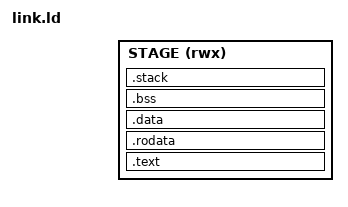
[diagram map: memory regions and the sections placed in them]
/* Lichen v3 boot stage (#615). One region (region.ld, generated by build.rs: STAGE_BASE, STAGE_LEN): the loaded image
 * first, then bss and the stack. The stage is written to 0x2000..0x7FFF (24 KB) one day, so check.sh holds the
 * packed image to 24576 bytes. Never writes outside its region; the kernel it chains to loads below 0x4FF28ED0. */
OUTPUT_ARCH(riscv)
ENTRY(_start)
INCLUDE region.ld
MEMORY {
  STAGE (rwx) : ORIGIN = STAGE_BASE, LENGTH = STAGE_LEN
}
SECTIONS {
  .text : { KEEP(*(.text.boot)) *(.text.trap) *(.text .text.*) } > STAGE
  .rodata : ALIGN(4) { *(.rodata .rodata.*) *(.srodata .srodata.*) } > STAGE
  .data : ALIGN(4) { *(.data .data.*) *(.sdata .sdata.*) . = ALIGN(4); } > STAGE
  .bss (NOLOAD) : ALIGN(16) { _sbss = .; *(.bss .bss.*) *(.sbss .sbss.*) *(COMMON) . = ALIGN(16); _ebss = .; } > STAGE
  .stack (NOLOAD) : ALIGN(16) { . += 24K; _stack_top = .; } > STAGE
  /DISCARD/ : { *(.eh_frame*) *(.comment) *(.riscv.attributes) }
  ASSERT(_stack_top <= STAGE_BASE + STAGE_LEN, "stage image, bss and stack overflow the stage window")
}
